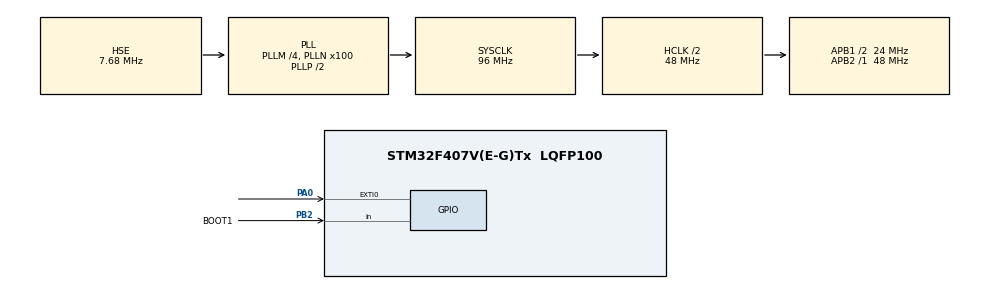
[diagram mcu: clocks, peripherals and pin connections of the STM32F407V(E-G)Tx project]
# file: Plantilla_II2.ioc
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Mcu.Family=STM32F4
Mcu.Name=STM32F407V(E-G)Tx
Mcu.Package=LQFP100
NVIC.EXTI0_IRQn=true\:0\:0\:false\:false\:true\:true\:true
NVIC.PriorityGroup=NVIC_PRIORITYGROUP_0
PA0-WKUP.Signal=GPXTI0
PA13.GPIO_Label=SWDIO
PA13.Mode=Trace_Asynchronous_SW
PA13.Signal=SYS_JTMS-SWDIO
PA14.GPIO_Label=SWCLK
PA14.Mode=Trace_Asynchronous_SW
PA14.Signal=SYS_JTCK-SWCLK
PB2.GPIO_Label=BOOT1
PB2.GPIO_Mode=GPIO_MODE_INPUT
PB2.GPIO_PuPd=GPIO_NOPULL
PB2.Signal=GPIO_Input
PB3.GPIO_Label=SWO
PB3.Mode=Trace_Asynchronous_SW
PB3.Signal=SYS_JTDO-SWO
PC14-OSC32_IN.GPIO_Label=PC14-OSC32_IN
PC14-OSC32_IN.Mode=LSE-External-Oscillator
PC14-OSC32_IN.Signal=RCC_OSC32_IN
PC15-OSC32_OUT.GPIO_Label=PC15-OSC32_OUT
PC15-OSC32_OUT.Mode=LSE-External-Oscillator
PC15-OSC32_OUT.Signal=RCC_OSC32_OUT
PH0-OSC_IN.GPIO_Label=PH0-OSC_IN
PH0-OSC_IN.Mode=HSE-External-Oscillator
PH0-OSC_IN.Signal=RCC_OSC_IN
PH1-OSC_OUT.GPIO_Label=PH1-OSC_OUT
PH1-OSC_OUT.Mode=HSE-External-Oscillator
PH1-OSC_OUT.Signal=RCC_OSC_OUT
ProjectManager.HeapSize=0x200
ProjectManager.StackSize=0x400
ProjectManager.TargetToolchain=MDK-ARM V5.27
RCC.48MHZClocksFreq_Value=27428571.42857143
RCC.AHBCLKDivider=RCC_SYSCLK_DIV2
RCC.AHBFreq_Value=48000000
RCC.APB1CLKDivider=RCC_HCLK_DIV2
RCC.APB1Freq_Value=24000000
RCC.APB1TimFreq_Value=48000000
RCC.APB2Freq_Value=48000000
RCC.APB2TimFreq_Value=48000000
RCC.CortexFreq_Value=48000000
RCC.HCLKFreq_Value=48000000
RCC.HSE_VALUE=7680000
RCC.HSI_VALUE=16000000
RCC.PLLM=4
RCC.PLLN=100
RCC.PLLQ=7
RCC.PLLSourceVirtual=RCC_PLLSOURCE_HSE
RCC.SYSCLKFreq_VALUE=96000000
RCC.SYSCLKSource=RCC_SYSCLKSOURCE_PLLCLK
RCC.VCOOutputFreq_Value=192000000
board=STM32F407G-DISC1

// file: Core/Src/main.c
/* USER CODE BEGIN Header */
/**
  ******************************************************************************
  * @file           : main.c
  * @brief          : Main program body
  ******************************************************************************
  * @attention
  *
  * <h2><center>&copy; Copyright (c) 2022 STMicroelectronics.
  * All rights reserved.</center></h2>
  *
  * This software component is licensed by ST under BSD 3-Clause license,
  * the "License"; You may not use this file except in compliance with the
  * License. You may obtain a copy of the License at:
  *                        opensource.org/licenses/BSD-3-Clause
  *
  ******************************************************************************
  */
/* USER CODE END Header */
#include "main.h"
#include "gpio.h"

void SystemClock_Config(void);

/* USER CODE BEGIN 0 */
AUX_FLAGS FLAGS = {0};
volatile int position=0;
volatile uint32_t timeStartMotor=0;
volatile uint32_t lastuwTick=0;
volatile uint32_t currentms = 0, ticks = 0 ;
STATE ESTADOS;
    /* USER CODE END 0 */

int main(void)
{

  /* MCU Configuration--------------------------------------------------------*/

  /* Reset of all peripherals, Initializes the Flash interface and the Systick. */
  HAL_Init();

  /* Configure the system clock */
  SystemClock_Config();

  /* Initialize all configured peripherals */
  MX_GPIO_Init();
  /* USER CODE BEGIN 2 */
  LED_Init();
  liftInit();
  motorInit();
  BLUELEDON;
  REDLEDON;
  GREENLEDON;
  ORANGELEDON;
  HAL_SYSTICK_Config(SystemCoreClock/1000);
  /* USER CODE END 2 */

  /* Infinite loop */
  /* USER CODE BEGIN WHILE */
  while (1)
  {
      LED_Update();
      lift_Update();
      motor_Update();
    /* USER CODE END WHILE */

  }
}

void SystemClock_Config(void)
{
  RCC_OscInitTypeDef RCC_OscInitStruct = {0};
  RCC_ClkInitTypeDef RCC_ClkInitStruct = {0};

  /** Configure the main internal regulator output voltage
  */
  __HAL_RCC_PWR_CLK_ENABLE();
  __HAL_PWR_VOLTAGESCALING_CONFIG(PWR_REGULATOR_VOLTAGE_SCALE1);
  /** Initializes the RCC Oscillators according to the specified parameters
  * in the RCC_OscInitTypeDef structure.
  */
  RCC_OscInitStruct.OscillatorType = RCC_OSCILLATORTYPE_HSE;
  RCC_OscInitStruct.HSEState = RCC_HSE_ON;
  RCC_OscInitStruct.PLL.PLLState = RCC_PLL_ON;
  RCC_OscInitStruct.PLL.PLLSource = RCC_PLLSOURCE_HSE;
  RCC_OscInitStruct.PLL.PLLM = 4;
  RCC_OscInitStruct.PLL.PLLN = 100;
  RCC_OscInitStruct.PLL.PLLP = RCC_PLLP_DIV2;
  RCC_OscInitStruct.PLL.PLLQ = 7;
  if (HAL_RCC_OscConfig(&RCC_OscInitStruct) != HAL_OK)
  {
    Error_Handler();
  }
  /** Initializes the CPU, AHB and APB buses clocks
  */
  RCC_ClkInitStruct.ClockType = RCC_CLOCKTYPE_HCLK|RCC_CLOCKTYPE_SYSCLK
                              |RCC_CLOCKTYPE_PCLK1|RCC_CLOCKTYPE_PCLK2;
  RCC_ClkInitStruct.SYSCLKSource = RCC_SYSCLKSOURCE_PLLCLK;
  RCC_ClkInitStruct.AHBCLKDivider = RCC_SYSCLK_DIV2;
  RCC_ClkInitStruct.APB1CLKDivider = RCC_HCLK_DIV2;
  RCC_ClkInitStruct.APB2CLKDivider = RCC_HCLK_DIV1;

  if (HAL_RCC_ClockConfig(&RCC_ClkInitStruct, FLASH_LATENCY_1) != HAL_OK)
  {
    Error_Handler();
  }
}

void Error_Handler(void)
{
  __disable_irq();
  while (1)
  {
  }
}

/************************ (C) COPYRIGHT STMicroelectronics *****END OF FILE****/
